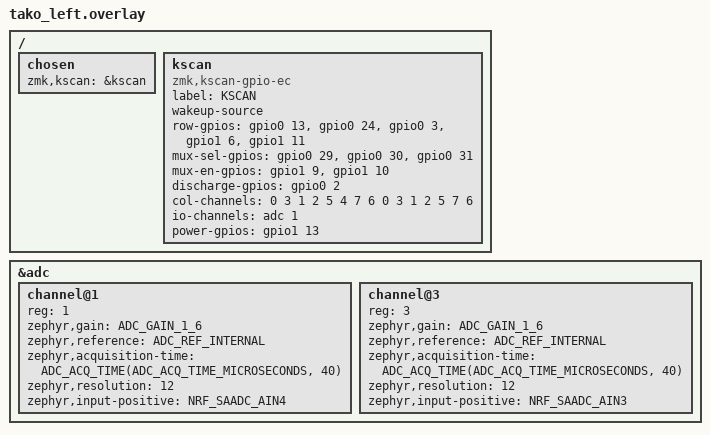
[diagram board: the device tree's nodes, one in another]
/*
 * Copyright (c) 2023 ssbb
 *
 * SPDX-License-Identifier: MIT
 */

#include "tako.dtsi"

/ {
  chosen {
    zmk,kscan = &kscan;
  };

    /* &gpio0 13 -> P0.13  (ROW 0)*/
    /* &gpio0 24 -> P0.24  (ROW 1)*/
    /* &gpio0 3 -> P0.03  (ROW 2)*/
    /* &gpio1 6 -> P1.06  (ROW 3)*/
    /* &gpio1 11 -> P1.11  (ROW 4)*/

  kscan: kscan {
    compatible = "zmk,kscan-gpio-ec";
    label = "KSCAN";
    wakeup-source;

    row-gpios
    = <&gpio0 13 GPIO_ACTIVE_HIGH>
    , <&gpio0 24 GPIO_ACTIVE_HIGH>
    , <&gpio0 3 GPIO_ACTIVE_HIGH>
    , <&gpio1 6 GPIO_ACTIVE_HIGH>
    , <&gpio1 11 GPIO_ACTIVE_HIGH>
    ;

    // mux select gpios for selecting which col channel to scan
    /* AI5 -> P0.29 (AMUX_SEL_0) */
    /* AI6 -> P0.30 (AMUX_SEL_0) */
    /* AI7 -> P0.31 (AMUX_SEL_0) */
    mux-sel-gpios
    = <&gpio0 29 GPIO_ACTIVE_HIGH>
    , <&gpio0 30 GPIO_ACTIVE_HIGH>
    , <&gpio0 31 GPIO_ACTIVE_HIGH>
    ;

    // 2 multiplexer enable pins in col number ascending order
    mux-en-gpios 
    = <&gpio1 9 GPIO_ACTIVE_HIGH>
    , <&gpio1 10 GPIO_ACTIVE_HIGH>
    ;
    discharge-gpios = <&gpio0 2 GPIO_ACTIVE_HIGH>;
    col-channels = <0 3 1 2 5 4 7 6 0 3 1 2 5 7 6>;
    io-channels = <&adc 1>;
    power-gpios = <&gpio1 13 GPIO_ACTIVE_HIGH>;
  };
};

&adc {
  #address-cells = <1>;
  #size-cells = <0>;
  status = "okay";

  // EC Read
  channel@1 {
    reg = <1>;
    zephyr,gain = "ADC_GAIN_1_6";
    zephyr,reference = "ADC_REF_INTERNAL";
    zephyr,acquisition-time = <ADC_ACQ_TIME(ADC_ACQ_TIME_MICROSECONDS, 40)>;
    zephyr,resolution = <12>;
    zephyr,input-positive = <NRF_SAADC_AIN4>; /* P0.28 */
  };

  // Battery Sensing
  channel@3 {
    reg = <3>;
    zephyr,gain = "ADC_GAIN_1_6";
    zephyr,reference = "ADC_REF_INTERNAL";
    zephyr,acquisition-time = <ADC_ACQ_TIME(ADC_ACQ_TIME_MICROSECONDS, 40)>;
    zephyr,resolution = <12>;
    zephyr,input-positive = <NRF_SAADC_AIN3>; /* P0.05 */
  };
};

